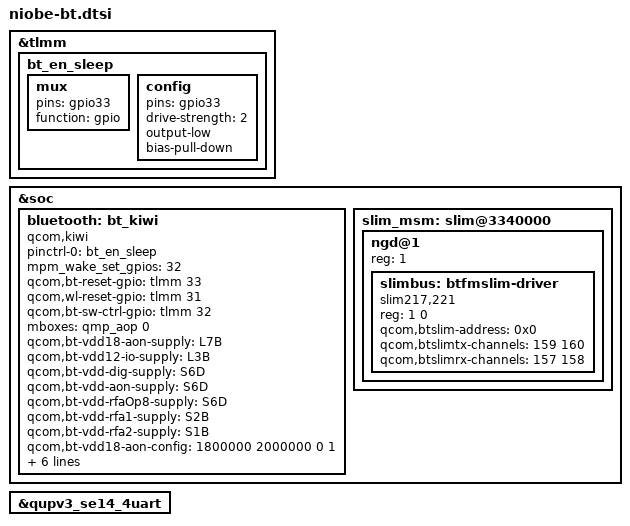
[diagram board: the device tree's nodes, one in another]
#include <dt-bindings/interconnect/qcom,pineapple.h>

&tlmm {
        bt_en_sleep: bt_en_sleep {
                mux {
                        pins = "gpio33";
                        function = "gpio";
                };

                config {
                        pins = "gpio33";
                        drive-strength = <2>;
                        output-low;
                        bias-pull-down;
                };
        };
};

&soc {
	bluetooth: bt_kiwi {
			compatible = "qcom,kiwi";
			pinctrl-names = "bt_en_sleep";
			pinctrl-0 = <&bt_en_sleep>;
			/* List of GPIOs to be setup for interrupt wakeup capable*/
			mpm_wake_set_gpios = <32>;
			qcom,bt-reset-gpio = <&tlmm 33 0>; /* BT_EN */
			qcom,wl-reset-gpio = <&tlmm 31 0>; /* WL_EN */
			qcom,bt-sw-ctrl-gpio = <&tlmm 32 0>; /* SW_CTRL */
			mboxes = <&qmp_aop 0>;

			qcom,bt-vdd18-aon-supply  = <&L7B>; /* BT VDD1.8 AON */
			qcom,bt-vdd12-io-supply   = <&L3B>;  /* BT VDD1.2V IO */
			qcom,bt-vdd-dig-supply    = <&S6D>;  /* BT LDO*/
			qcom,bt-vdd-aon-supply    = <&S6D>;  /* BT AON LDO*/
			qcom,bt-vdd-rfaOp8-supply = <&S6D>;  /* BT RFAOp8 CMN LDO*/
			qcom,bt-vdd-rfa1-supply   = <&S2B>;  /* BT RFA1.2 LDO */
			qcom,bt-vdd-rfa2-supply   = <&S1B>;  /* BT RFA1.8 LDO */

			qcom,bt-vdd18-aon-config  = <1800000 2000000 0 1>;
			qcom,bt-vdd12-io-config   = <1200000 1980000 0 1>;
			qcom,bt-vdd-dig-config    = <916000 2100000 0 1>;
			qcom,bt-vdd-aon-config    = <916000 2100000 0 1>;
			qcom,bt-vdd-rfaOp8-config = <916000 2100000 0 1>;
			qcom,bt-vdd-rfa1-config   = <1316000 2100000 0 1>;
			qcom,bt-vdd-rfa2-config   = <1864000 2100000 0 1>;

	};

	slim_msm: slim@3340000 {
		status =  "ok";
		ngd@1 {
			reg = <1>;
			#address-cells = <1>;
			#size-cells = <1>;
			//slimbus child nodes
			slimbus: btfmslim-driver {
				compatible = "slim217,221";
				reg = <1 0>;
				qcom,btslim-address  = <0x0>; /* BT SLIM EP address*/
				qcom,btslimtx-channels = <159 160>; /* slimbus FM_Tx, SCO_Tx channels */
				qcom,btslimrx-channels = <157 158>; /* slimbus SCO_A2DP_Rx A2DP_Rx */
			};
		};
	};
};

//uart instance
&qupv3_se14_4uart {
       status = "ok";
};
